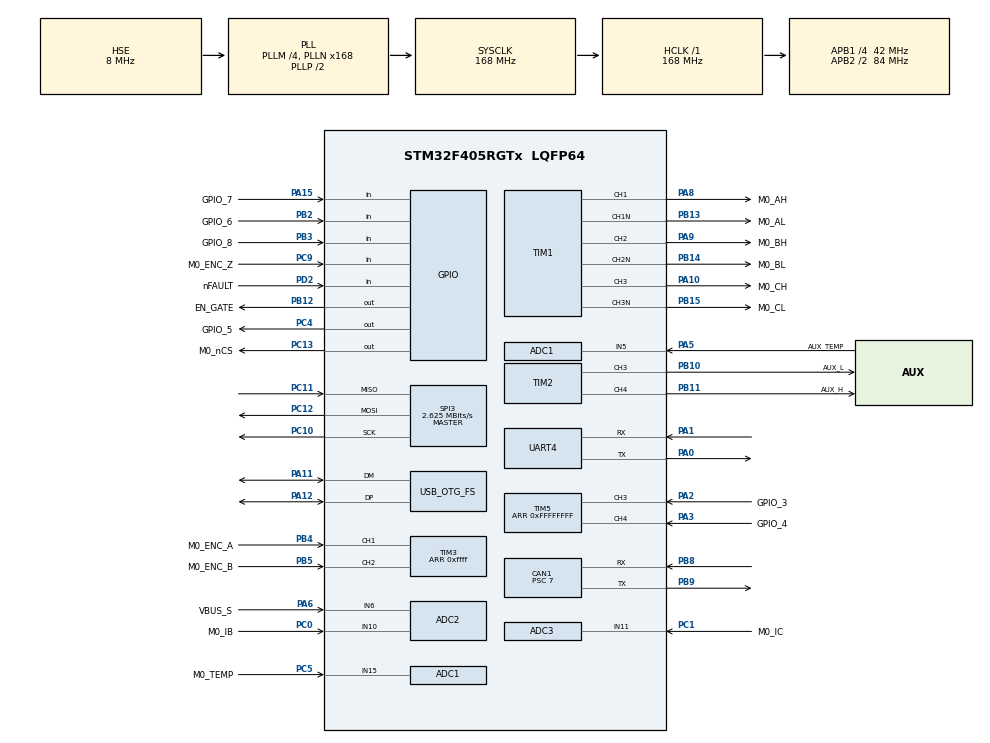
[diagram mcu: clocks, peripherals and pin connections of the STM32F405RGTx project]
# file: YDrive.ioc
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ADC1.Channel-0\#ChannelRegularConversion=ADC_CHANNEL_6
ADC1.Channel-1\#ChannelInjectedConversion=ADC_CHANNEL_6
ADC1.ClockPrescaler=ADC_CLOCK_SYNC_PCLK_DIV4
ADC1.ExternalTrigInjecConv=ADC_EXTERNALTRIGINJECCONV_T1_TRGO
ADC1.ExternalTrigInjecConvEdge=ADC_EXTERNALTRIGINJECCONVEDGE_RISING
ADC1.InjNumberOfConversion=1
ADC1.InjectedOffset-1\#ChannelInjectedConversion=0
ADC1.InjectedRank-1\#ChannelInjectedConversion=1
ADC1.NbrOfConversion=1
ADC1.NbrOfConversionFlag=1
ADC1.Rank-0\#ChannelRegularConversion=1
ADC1.SamplingTime-0\#ChannelRegularConversion=ADC_SAMPLETIME_3CYCLES
ADC1.SamplingTime-1\#ChannelInjectedConversion=ADC_SAMPLETIME_3CYCLES
ADC1.master=1
ADC2.Channel-0\#ChannelRegularConversion=ADC_CHANNEL_10
ADC2.Channel-1\#ChannelInjectedConversion=ADC_CHANNEL_10
ADC2.ClockPrescaler=ADC_CLOCK_SYNC_PCLK_DIV4
ADC2.ExternalTrigConv=ADC_SOFTWARE_START
ADC2.ExternalTrigInjecConv=ADC_EXTERNALTRIGINJECCONV_T1_TRGO
ADC2.ExternalTrigInjecConvEdge=ADC_EXTERNALTRIGINJECCONVEDGE_RISING
ADC2.InjNumberOfConversion=1
ADC2.InjectedOffset-1\#ChannelInjectedConversion=0
ADC2.InjectedRank-1\#ChannelInjectedConversion=1
ADC2.NbrOfConversion=1
ADC2.NbrOfConversionFlag=1
ADC2.Rank-0\#ChannelRegularConversion=1
ADC2.SamplingTime-0\#ChannelRegularConversion=ADC_SAMPLETIME_3CYCLES
ADC2.SamplingTime-1\#ChannelInjectedConversion=ADC_SAMPLETIME_3CYCLES
ADC3.Channel-0\#ChannelRegularConversion=ADC_CHANNEL_11
ADC3.Channel-1\#ChannelInjectedConversion=ADC_CHANNEL_11
ADC3.ClockPrescaler=ADC_CLOCK_SYNC_PCLK_DIV4
ADC3.ExternalTrigInjecConv=ADC_EXTERNALTRIGINJECCONV_T1_TRGO
ADC3.ExternalTrigInjecConvEdge=ADC_EXTERNALTRIGINJECCONVEDGE_RISING
ADC3.InjNumberOfConversion=1
ADC3.InjectedOffset-1\#ChannelInjectedConversion=0
ADC3.InjectedRank-1\#ChannelInjectedConversion=1
ADC3.NbrOfConversionFlag=1
ADC3.Rank-0\#ChannelRegularConversion=1
ADC3.SamplingTime-0\#ChannelRegularConversion=ADC_SAMPLETIME_3CYCLES
ADC3.SamplingTime-1\#ChannelInjectedConversion=ADC_SAMPLETIME_3CYCLES
CAN1.BS1=CAN_BS1_6TQ
CAN1.BS2=CAN_BS2_5TQ
CAN1.CalculateBaudRate=499999
CAN1.CalculateTimeBit=2000
CAN1.CalculateTimeQuantum=166.66666666666669
CAN1.Prescaler=7
Dma.ADC1.2.Direction=DMA_PERIPH_TO_MEMORY
Dma.ADC1.2.FIFOMode=DMA_FIFOMODE_DISABLE
Dma.ADC1.2.Instance=DMA2_Stream0
Dma.ADC1.2.MemDataAlignment=DMA_MDATAALIGN_HALFWORD
Dma.ADC1.2.MemInc=DMA_MINC_ENABLE
Dma.ADC1.2.Mode=DMA_CIRCULAR
Dma.ADC1.2.PeriphDataAlignment=DMA_PDATAALIGN_HALFWORD
Dma.ADC1.2.PeriphInc=DMA_PINC_DISABLE
Dma.ADC1.2.Priority=DMA_PRIORITY_LOW
Dma.Request0=SPI3_TX
Dma.Request1=SPI3_RX
Dma.Request2=ADC1
Dma.SPI3_RX.1.Direction=DMA_PERIPH_TO_MEMORY
Dma.SPI3_RX.1.FIFOMode=DMA_FIFOMODE_DISABLE
Dma.SPI3_RX.1.Instance=DMA1_Stream0
Dma.SPI3_RX.1.MemDataAlignment=DMA_MDATAALIGN_HALFWORD
Dma.SPI3_RX.1.MemInc=DMA_MINC_ENABLE
Dma.SPI3_RX.1.Mode=DMA_NORMAL
Dma.SPI3_RX.1.PeriphDataAlignment=DMA_PDATAALIGN_HALFWORD
Dma.SPI3_RX.1.PeriphInc=DMA_PINC_DISABLE
Dma.SPI3_RX.1.Priority=DMA_PRIORITY_MEDIUM
Dma.SPI3_TX.0.Direction=DMA_MEMORY_TO_PERIPH
Dma.SPI3_TX.0.FIFOMode=DMA_FIFOMODE_DISABLE
Dma.SPI3_TX.0.Instance=DMA1_Stream5
Dma.SPI3_TX.0.MemDataAlignment=DMA_MDATAALIGN_HALFWORD
Dma.SPI3_TX.0.MemInc=DMA_MINC_ENABLE
Dma.SPI3_TX.0.Mode=DMA_NORMAL
Dma.SPI3_TX.0.PeriphDataAlignment=DMA_PDATAALIGN_HALFWORD
Dma.SPI3_TX.0.PeriphInc=DMA_PINC_DISABLE
Dma.SPI3_TX.0.Priority=DMA_PRIORITY_MEDIUM
FREERTOS.Tasks01=defaultTask,24,512,StartDefaultTask,Default,NULL,Dynamic,NULL,NULL
Mcu.Family=STM32F4
Mcu.Name=STM32F405RGTx
Mcu.Package=LQFP64
Mcu.UserConstants=TIM_1_8_PERIOD_CLOCKS,3500;TIM_APB1_CLOCK_HZ,84000000;TIM_APB1_DEADTIME_CLOCKS,40;TIM_APB1_PERIOD_CLOCKS,4096;TIM_1_8_RCR,2;TIM_1_8_DEADTIME_CLOCKS,20;TIM_1_8_CLOCK_HZ,168000000
NVIC.ADC_IRQn=true\:5\:0\:true\:false\:true\:false\:true\:true\:true
NVIC.CAN1_RX0_IRQn=true\:6\:0\:true\:false\:true\:false\:true\:true\:true
NVIC.CAN1_RX1_IRQn=true\:6\:0\:true\:false\:true\:false\:true\:true\:true
NVIC.CAN1_SCE_IRQn=true\:6\:0\:true\:false\:true\:false\:true\:true\:true
NVIC.CAN1_TX_IRQn=true\:6\:0\:true\:false\:true\:false\:true\:true\:true
NVIC.DMA1_Stream0_IRQn=true\:5\:0\:true\:false\:true\:false\:false\:true\:true
NVIC.DMA1_Stream5_IRQn=true\:5\:0\:true\:false\:true\:false\:false\:true\:true
NVIC.DMA2_Stream0_IRQn=true\:5\:0\:true\:false\:true\:false\:false\:true\:true
NVIC.OTG_FS_IRQn=true\:5\:0\:true\:false\:true\:false\:false\:true\:true
NVIC.PriorityGroup=NVIC_PRIORITYGROUP_4
NVIC.SPI3_IRQn=true\:5\:0\:true\:false\:true\:false\:true\:true\:true
NVIC.TIM1_UP_TIM10_IRQn=true\:0\:0\:true\:false\:true\:false\:true\:true\:true
NVIC.TIM5_IRQn=true\:5\:0\:true\:false\:true\:false\:true\:true\:true
NVIC.TIM8_TRG_COM_TIM14_IRQn=true\:0\:0\:true\:false\:true\:false\:false\:true\:true
NVIC.TIM8_UP_TIM13_IRQn=true\:0\:0\:true\:false\:true\:false\:true\:true\:true
NVIC.TimeBase=TIM8_TRG_COM_TIM14_IRQn
NVIC.TimeBaseIP=TIM14
NVIC.UART4_IRQn=true\:6\:0\:true\:false\:true\:false\:true\:true\:true
PA0-WKUP.Mode=Asynchronous
PA0-WKUP.Signal=UART4_TX
PA1.Mode=Asynchronous
PA1.Signal=UART4_RX
PA10.GPIO_Label=M0_CH
PA10.Signal=S_TIM1_CH3
PA11.Mode=Device_Only
PA11.Signal=USB_OTG_FS_DM
PA12.Mode=Device_Only
PA12.Signal=USB_OTG_FS_DP
PA13.Mode=Serial_Wire
PA13.Signal=SYS_JTMS-SWDIO
PA14.Mode=Serial_Wire
PA14.Signal=SYS_JTCK-SWCLK
PA15.GPIO_Label=GPIO_7
PA15.Signal=GPIO_Input
PA2.GPIO_Label=GPIO_3
PA2.Signal=S_TIM5_CH3
PA3.GPIO_Label=GPIO_4
PA3.Signal=S_TIM5_CH4
PA5.GPIO_Label=AUX_TEMP
PA5.Signal=ADCx_IN5
PA6.GPIO_Label=VBUS_S
PA6.Signal=ADCx_IN6
PA8.GPIO_Label=M0_AH
PA8.Signal=S_TIM1_CH1
PA9.GPIO_Label=M0_BH
PA9.Signal=S_TIM1_CH2
PB10.GPIO_Label=AUX_L
PB10.Signal=S_TIM2_CH3
PB11.GPIO_Label=AUX_H
PB11.Signal=S_TIM2_CH4
PB12.GPIO_Label=EN_GATE
PB12.Signal=GPIO_Output
PB13.GPIO_Label=M0_AL
PB13.Mode=PWM Generation1 CH1 CH1N
PB13.Signal=TIM1_CH1N
PB14.GPIO_Label=M0_BL
PB14.Mode=PWM Generation2 CH2 CH2N
PB14.Signal=TIM1_CH2N
PB15.GPIO_Label=M0_CL
PB15.Mode=PWM Generation3 CH3 CH3N
PB15.Signal=TIM1_CH3N
PB2.GPIO_Label=GPIO_6
PB2.Signal=GPIO_Input
PB3.GPIO_Label=GPIO_8
PB3.Signal=GPIO_Input
PB4.GPIO_Label=M0_ENC_A
PB4.GPIO_PuPd=GPIO_PULLUP
PB4.Signal=S_TIM3_CH1
PB5.GPIO_Label=M0_ENC_B
PB5.GPIO_PuPd=GPIO_PULLUP
PB5.Signal=S_TIM3_CH2
PB8.Mode=CAN_Activate
PB8.Signal=CAN1_RX
PB9.Mode=CAN_Activate
PB9.Signal=CAN1_TX
PC0.GPIO_Label=M0_IB
PC0.Signal=ADCx_IN10
PC1.GPIO_Label=M0_IC
PC1.Signal=ADCx_IN11
PC10.Mode=Full_Duplex_Master
PC10.Signal=SPI3_SCK
PC11.Mode=Full_Duplex_Master
PC11.Signal=SPI3_MISO
PC12.Mode=Full_Duplex_Master
PC12.Signal=SPI3_MOSI
PC13-ANTI_TAMP.GPIO_Label=M0_nCS
PC13-ANTI_TAMP.PinState=GPIO_PIN_SET
PC13-ANTI_TAMP.Signal=GPIO_Output
PC4.GPIO_Label=GPIO_5
PC4.PinState=GPIO_PIN_SET
PC4.Signal=GPIO_Output
PC5.GPIO_Label=M0_TEMP
PC5.Signal=ADCx_IN15
PC9.GPIO_Label=M0_ENC_Z
PC9.Signal=GPIO_Input
PD2.GPIO_Label=nFAULT
PD2.GPIO_PuPd=GPIO_PULLUP
PD2.Signal=GPIO_Input
PH0-OSC_IN.Mode=HSE-External-Oscillator
PH0-OSC_IN.Signal=RCC_OSC_IN
PH1-OSC_OUT.Mode=HSE-External-Oscillator
PH1-OSC_OUT.Signal=RCC_OSC_OUT
ProjectManager.HeapSize=0x200
ProjectManager.StackSize=0x400
ProjectManager.TargetToolchain=CMake
RCC.48MHZClocksFreq_Value=48000000
RCC.AHBFreq_Value=168000000
RCC.APB1CLKDivider=RCC_HCLK_DIV4
RCC.APB1Freq_Value=42000000
RCC.APB1TimFreq_Value=84000000
RCC.APB2CLKDivider=RCC_HCLK_DIV2
RCC.APB2Freq_Value=84000000
RCC.APB2TimFreq_Value=168000000
RCC.CortexFreq_Value=168000000
RCC.HCLKFreq_Value=168000000
RCC.HSE_VALUE=8000000
RCC.HSI_VALUE=16000000
RCC.LSE_VALUE=32768
RCC.PLLM=4
RCC.PLLN=168
RCC.PLLQ=7
RCC.SYSCLKFreq_VALUE=168000000
RCC.SYSCLKSource=RCC_SYSCLKSOURCE_PLLCLK
RCC.VCOOutputFreq_Value=336000000
SH.ADCx_IN10.0=ADC2_IN10,IN10
SH.ADCx_IN10.1=ADC1_IN10,IN10
SH.ADCx_IN10.2=ADC3_IN10,IN10
SH.ADCx_IN11.0=ADC3_IN11,IN11
SH.ADCx_IN11.1=ADC1_IN11,IN11
SH.ADCx_IN11.2=ADC2_IN11,IN11
SH.ADCx_IN15.0=ADC1_IN15,IN15
SH.ADCx_IN15.1=ADC2_IN15,IN15
SH.ADCx_IN5.0=ADC1_IN5,IN5
SH.ADCx_IN5.1=ADC2_IN5,IN5
SH.ADCx_IN6.0=ADC2_IN6,IN6
SH.ADCx_IN6.1=ADC1_IN6,IN6
SH.S_TIM1_CH1.0=TIM1_CH1,PWM Generation1 CH1 CH1N
SH.S_TIM1_CH2.0=TIM1_CH2,PWM Generation2 CH2 CH2N
SH.S_TIM1_CH3.0=TIM1_CH3,PWM Generation3 CH3 CH3N
SH.S_TIM2_CH3.0=TIM2_CH3,PWM Generation3 CH3
SH.S_TIM2_CH4.0=TIM2_CH4,PWM Generation4 CH4
SH.S_TIM3_CH1.0=TIM3_CH1,Encoder_Interface
SH.S_TIM3_CH2.0=TIM3_CH2,Encoder_Interface
SH.S_TIM5_CH3.0=TIM5_CH3,Input_Capture3_from_TI3
SH.S_TIM5_CH4.0=TIM5_CH4,Input_Capture4_from_TI4
SPI3.BaudRatePrescaler=SPI_BAUDRATEPRESCALER_16
SPI3.CLKPhase=SPI_PHASE_2EDGE
SPI3.CalculateBaudRate=2.625 MBits/s
SPI3.DataSize=SPI_DATASIZE_16BIT
SPI3.Direction=SPI_DIRECTION_2LINES
SPI3.Mode=SPI_MODE_MASTER
SPI3.VirtualType=VM_MASTER
TIM1.AutomaticOutput=TIM_AUTOMATICOUTPUT_DISABLE
TIM1.Channel-Output\ Compare4\ No\ Output=TIM_CHANNEL_4
TIM1.Channel-PWM\ Generation1\ CH1\ CH1N=TIM_CHANNEL_1
TIM1.Channel-PWM\ Generation2\ CH2\ CH2N=TIM_CHANNEL_2
TIM1.Channel-PWM\ Generation3\ CH3\ CH3N=TIM_CHANNEL_3
TIM1.CounterMode=TIM_COUNTERMODE_CENTERALIGNED3
TIM1.DeadTime=TIM_1_8_DEADTIME_CLOCKS
TIM1.OCMode_PWM-PWM\ Generation1\ CH1\ CH1N=TIM_OCMODE_PWM2
TIM1.OCMode_PWM-PWM\ Generation2\ CH2\ CH2N=TIM_OCMODE_PWM2
TIM1.OCMode_PWM-PWM\ Generation3\ CH3\ CH3N=TIM_OCMODE_PWM2
TIM1.OffStateIDLEMode=TIM_OSSI_ENABLE
TIM1.OffStateRunMode=TIM_OSSR_ENABLE
TIM1.Period=TIM_1_8_PERIOD_CLOCKS
TIM1.Pulse-PWM\ Generation1\ CH1\ CH1N=0
TIM1.Pulse-PWM\ Generation2\ CH2\ CH2N=0
TIM1.Pulse-PWM\ Generation3\ CH3\ CH3N=0
TIM1.RepetitionCounter=TIM_1_8_RCR
TIM1.TIM_MasterOutputTrigger=TIM_TRGO_UPDATE
TIM1.TIM_MasterSlaveMode=TIM_MASTERSLAVEMODE_DISABLE
TIM13.Period=(2 * TIM_1_8_PERIOD_CLOCKS * (TIM_1_8_RCR+1)) * (TIM_APB1_CLOCK_HZ / TIM_1_8_CLOCK_HZ)
TIM2.AutoReloadPreload=TIM_AUTORELOAD_PRELOAD_DISABLE
TIM2.Channel-PWM\ Generation3\ CH3=TIM_CHANNEL_3
TIM2.Channel-PWM\ Generation4\ CH4=TIM_CHANNEL_4
TIM2.CounterMode=TIM_COUNTERMODE_CENTERALIGNED3
TIM2.OCMode_PWM-PWM\ Generation3\ CH3=TIM_OCMODE_PWM2
TIM2.OCMode_PWM-PWM\ Generation4\ CH4=TIM_OCMODE_PWM2
TIM2.OCPolarity_3=TIM_OCPOLARITY_LOW
TIM2.OCPolarity_4=TIM_OCPOLARITY_HIGH
TIM2.Period=TIM_APB1_PERIOD_CLOCKS
TIM3.EncoderMode=TIM_ENCODERMODE_TI12
TIM3.IC1Filter=4
TIM3.IC1Polarity=TIM_ICPOLARITY_RISING
TIM3.IC2Filter=4
TIM3.IC2Polarity=TIM_ICPOLARITY_RISING
TIM3.Period=0xffff
TIM5.Channel-Input_Capture3_from_TI3=TIM_CHANNEL_3
TIM5.Channel-Input_Capture4_from_TI4=TIM_CHANNEL_4
TIM5.ICFilter_CH3=15
TIM5.ICFilter_CH4=15
TIM5.ICPolarity_CH3=TIM_INPUTCHANNELPOLARITY_BOTHEDGE
TIM5.ICPolarity_CH4=TIM_INPUTCHANNELPOLARITY_BOTHEDGE
TIM5.Period=0xFFFFFFFF
UART4.VirtualMode=Asynchronous
USB_DEVICE.CLASS_NAME_FS=CDC
USB_DEVICE.VirtualMode-CDC_FS=Cdc
USB_DEVICE.VirtualModeFS=Cdc_FS
USB_OTG_FS.VirtualMode=Device_Only
VP_FREERTOS_VS_CMSIS_V2.Mode=CMSIS_V2
VP_SYS_VS_tim14.Mode=TIM14
VP_TIM13_VS_ClockSourceINT.Mode=Enable_Timer
VP_TIM1_VS_ClockSourceINT.Mode=Internal
VP_TIM1_VS_no_output4.Mode=Output Compare4 No Output
VP_USB_DEVICE_VS_USB_DEVICE_CDC_FS.Mode=CDC_FS
board=custom

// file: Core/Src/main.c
/* USER CODE BEGIN Header */
/**
  ******************************************************************************
  * @file           : main.c
  * @brief          : Main program body
  ******************************************************************************
  * @attention
  *
  * Copyright (c) 2026 STMicroelectronics.
  * All rights reserved.
  *
  * This software is licensed under terms that can be found in the LICENSE file
  * in the root directory of this software component.
  * If no LICENSE file comes with this software, it is provided AS-IS.
  *
  ******************************************************************************
  */
/* USER CODE END Header */
#include "main.h"
#include "cmsis_os.h"
#include "adc.h"
#include "can.h"
#include "dma.h"
#include "spi.h"
#include "tim.h"
#include "usart.h"
#include "usb_device.h"
#include "gpio.h"

void SystemClock_Config(void);
void MX_FREERTOS_Init(void);

int main(void)
{

  /* MCU Configuration--------------------------------------------------------*/

  /* Reset of all peripherals, Initializes the Flash interface and the Systick. */
  HAL_Init();

  /* Configure the system clock */
  SystemClock_Config();

  /* Initialize all configured peripherals */
  MX_GPIO_Init();
  MX_DMA_Init();
  MX_ADC1_Init();
  MX_ADC2_Init();
  MX_ADC3_Init();
  MX_SPI3_Init();
  MX_TIM1_Init();
  MX_UART4_Init();
  MX_CAN1_Init();
  MX_TIM3_Init();
  MX_TIM2_Init();
  MX_TIM5_Init();
  MX_TIM13_Init();

  /* Init scheduler */
  osKernelInitialize();  /* Call init function for freertos objects (in cmsis_os2.c) */
  MX_FREERTOS_Init();

  /* Start scheduler */
  osKernelStart();

  /* We should never get here as control is now taken by the scheduler */

  /* Infinite loop */
  while (1)
  {

  }
}

void SystemClock_Config(void)
{
  RCC_OscInitTypeDef RCC_OscInitStruct = {0};
  RCC_ClkInitTypeDef RCC_ClkInitStruct = {0};

  /** Configure the main internal regulator output voltage
  */
  __HAL_RCC_PWR_CLK_ENABLE();
  __HAL_PWR_VOLTAGESCALING_CONFIG(PWR_REGULATOR_VOLTAGE_SCALE1);

  /** Initializes the RCC Oscillators according to the specified parameters
  * in the RCC_OscInitTypeDef structure.
  */
  RCC_OscInitStruct.OscillatorType = RCC_OSCILLATORTYPE_LSI|RCC_OSCILLATORTYPE_HSE;
  RCC_OscInitStruct.HSEState = RCC_HSE_ON;
  RCC_OscInitStruct.LSIState = RCC_LSI_ON;
  RCC_OscInitStruct.PLL.PLLState = RCC_PLL_ON;
  RCC_OscInitStruct.PLL.PLLSource = RCC_PLLSOURCE_HSE;
  RCC_OscInitStruct.PLL.PLLM = 4;
  RCC_OscInitStruct.PLL.PLLN = 168;
  RCC_OscInitStruct.PLL.PLLP = RCC_PLLP_DIV2;
  RCC_OscInitStruct.PLL.PLLQ = 7;
  if (HAL_RCC_OscConfig(&RCC_OscInitStruct) != HAL_OK)
  {
    Error_Handler();
  }

  /** Initializes the CPU, AHB and APB buses clocks
  */
  RCC_ClkInitStruct.ClockType = RCC_CLOCKTYPE_HCLK|RCC_CLOCKTYPE_SYSCLK
                              |RCC_CLOCKTYPE_PCLK1|RCC_CLOCKTYPE_PCLK2;
  RCC_ClkInitStruct.SYSCLKSource = RCC_SYSCLKSOURCE_PLLCLK;
  RCC_ClkInitStruct.AHBCLKDivider = RCC_SYSCLK_DIV1;
  RCC_ClkInitStruct.APB1CLKDivider = RCC_HCLK_DIV4;
  RCC_ClkInitStruct.APB2CLKDivider = RCC_HCLK_DIV2;

  if (HAL_RCC_ClockConfig(&RCC_ClkInitStruct, FLASH_LATENCY_5) != HAL_OK)
  {
    Error_Handler();
  }
}

void HAL_TIM_PeriodElapsedCallback(TIM_HandleTypeDef *htim)
{
  if (htim->Instance == TIM14)
  {
    HAL_IncTick();
  }
}

void Error_Handler(void)
{
  __disable_irq();
  while (1)
  {
  }
}

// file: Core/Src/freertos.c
/* USER CODE BEGIN Header */
/**
  ******************************************************************************
  * File Name          : freertos.c
  * Description        : Code for freertos applications
  ******************************************************************************
  * @attention
  *
  * Copyright (c) 2026 STMicroelectronics.
  * All rights reserved.
  *
  * This software is licensed under terms that can be found in the LICENSE file
  * in the root directory of this software component.
  * If no LICENSE file comes with this software, it is provided AS-IS.
  *
  ******************************************************************************
  */
/* USER CODE END Header */

#include "FreeRTOS.h"
#include "task.h"
#include "main.h"
#include "cmsis_os.h"

/* USER CODE BEGIN Includes */
#include "usb_device.h"
#include "axis.h"
#include "board.h"
#include "motor.h"
#include "usb_command.h"

/* USER CODE END Includes */

/* Definitions for defaultTask */
osThreadId_t defaultTaskHandle;
const osThreadAttr_t defaultTask_attributes = {
  .name = "defaultTask",
  .stack_size = 512 * 4,
  .priority = (osPriority_t) osPriorityNormal,
};

void StartDefaultTask(void *argument);

extern void MX_USB_DEVICE_Init(void);
void MX_FREERTOS_Init(void); /* (MISRA C 2004 rule 8.1) */

void MX_FREERTOS_Init(void) {

  /* Create the thread(s) */
  /* creation of defaultTask */
  defaultTaskHandle = osThreadNew(StartDefaultTask, NULL, &defaultTask_attributes);

}

void StartDefaultTask(void *argument)
{
  /* init code for USB_DEVICE */
  MX_USB_DEVICE_Init();
  /* USER CODE BEGIN StartDefaultTask */
  MX_USB_DEVICE_Init();
  osDelay(500);

  motor_para_init();
  motor_setup();
  motor_control_start();

  /* Infinite loop */
  for(;;)
  {
    USBcommander_run();
    run_state_machine_loop();
    osDelay(1);
  }
  /* USER CODE END StartDefaultTask */
}
